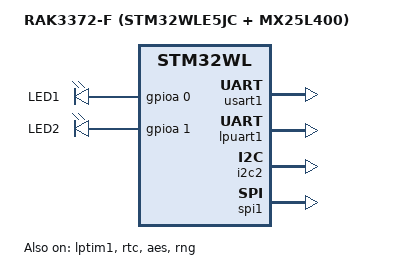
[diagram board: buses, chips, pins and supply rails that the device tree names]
/* SPDX-FileCopyrightText: Copyright (c) 2026 RAKwireless */
/* SPDX-License-Identifier: Apache-2.0 */
/*
 * Product board for the RAK3372-F (RAK3172-F WisDuo module, STM32WLE5JC + MX25L400).
 * Radio is the STM32WLE5 on-chip SUBGHZ (st,stm32wl-subghz-radio).
 * image-1 is the on-module SPI NOR, so LoRaWAN FUOTA installs by
 * overwrite. USP support is the STM32WL west patch in
 * zephyr/patches/usp_zephyr.
 * RUI3 default serial is lpuart1 (PA2/PA3, 115200). That is the console,
 * the AT port, and the RAK19007 USB-UART. UART1 remains usart1 (PB6/PB7).
 * USART2 is left disabled because it uses the same pins as LPUART1.
 */

/dts-v1/;
#include <rakwireless/rzi_rak3172_f.dtsi>
#include <zephyr/dt-bindings/gpio/gpio.h>
#include "rak3372_f-partitions.dtsi"

/ {
	model = "RAK3372-F (STM32WLE5JC + MX25L400)";
	compatible = "rakwireless,rak3372-f-stm32wl";

	chosen {
		zephyr,console = &lpuart1;
		zephyr,shell-uart = &lpuart1;
		zephyr,system-timer = &lptim1;
		zephyr,lorawan-transceiver = &lora;
	};

	leds {
		compatible = "gpio-leds";

		/* RAK3372-F carrier: LED1=PA0, LED2=PA1 */
		led1: led_1 {
			gpios = <&gpioa 0 GPIO_ACTIVE_HIGH>;
			label = "LED1";
		};

		led2: led_2 {
			gpios = <&gpioa 1 GPIO_ACTIVE_HIGH>;
			label = "LED2";
		};
	};

	aliases {
		led0 = &led1;
		lora0 = &lora;
		rzi-at-uart = &lpuart1;
		watchdog0 = &iwdg;
		spi-flash0 = &ext_flash;
	};
};

&lptim1 {
	status = "okay";
};

&usart1 {
	status = "okay";
};

&lpuart1 {
	status = "okay";
};

&i2c2 {
	status = "okay";
};

&spi1 {
	status = "okay";
};

&rtc {
	status = "okay";
};

&aes {
	status = "okay";
};

&rng {
	status = "okay";
};
